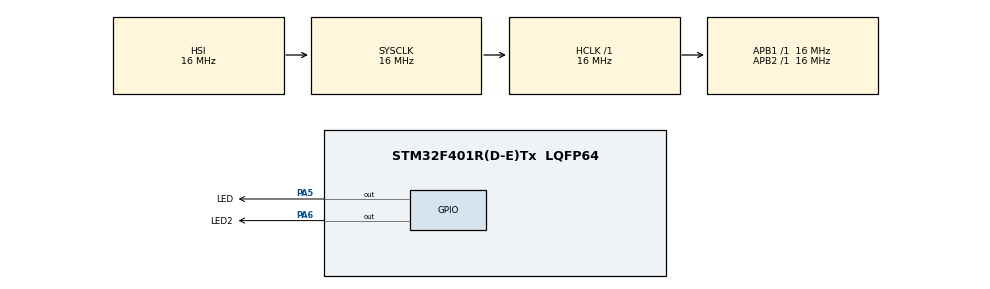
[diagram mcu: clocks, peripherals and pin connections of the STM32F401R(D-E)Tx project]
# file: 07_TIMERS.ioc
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Mcu.Family=STM32F4
Mcu.Name=STM32F401R(D-E)Tx
Mcu.Package=LQFP64
NVIC.PriorityGroup=NVIC_PRIORITYGROUP_4
NVIC.TIM1_TRG_COM_TIM11_IRQn=true\:0\:0\:false\:false\:true\:true\:true\:true
PA13.Mode=Serial_Wire
PA13.Signal=SYS_JTMS-SWDIO
PA14.Mode=Serial_Wire
PA14.Signal=SYS_JTCK-SWCLK
PA5.GPIO_Label=LED
PA5.Signal=GPIO_Output
PA6.GPIO_Label=LED2
PA6.Signal=GPIO_Output
ProjectManager.HeapSize=0x200
ProjectManager.StackSize=0x400
ProjectManager.TargetToolchain=STM32CubeIDE
RCC.AHBFreq_Value=16000000
RCC.APB1Freq_Value=16000000
RCC.APB2Freq_Value=16000000
RCC.CortexFreq_Value=16000000
RCC.HSE_VALUE=25000000
RCC.HSI_VALUE=16000000
RCC.LSE_VALUE=32768
RCC.SYSCLKFreq_VALUE=16000000
RCC.VCOOutputFreq_Value=192000000
TIM1.AutoReloadPreload=TIM_AUTORELOAD_PRELOAD_ENABLE
TIM1.Period=16000-1
TIM1.Prescaler=100-1
TIM11.AutoReloadPreload=TIM_AUTORELOAD_PRELOAD_ENABLE
TIM11.Period=16000-1
TIM11.Prescaler=100-1
VP_TIM11_VS_ClockSourceINT.Mode=Enable_Timer
VP_TIM1_VS_ClockSourceINT.Mode=Internal
board=custom

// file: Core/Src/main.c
/* USER CODE BEGIN Header */
/**
  ******************************************************************************
  * @file           : main.c
  * @brief          : Main program body
  ******************************************************************************
  * @attention
  *
  * Copyright (c) 2023 STMicroelectronics.
  * All rights reserved.
  *
  * This software is licensed under terms that can be found in the LICENSE file
  * in the root directory of this software component.
  * If no LICENSE file comes with this software, it is provided AS-IS.
  *
  ******************************************************************************
  */
/* USER CODE END Header */
#include "main.h"

TIM_HandleTypeDef htim1;
TIM_HandleTypeDef htim11;

void SystemClock_Config(void);
static void MX_GPIO_Init(void);
static void MX_TIM11_Init(void);
static void MX_TIM1_Init(void);

int main(void)
{

  /* MCU Configuration--------------------------------------------------------*/

  /* Reset of all peripherals, Initializes the Flash interface and the Systick. */
  HAL_Init();

  /* Configure the system clock */
  SystemClock_Config();

  /* USER CODE BEGIN SysInit */

  /*FORMULA DEL TIMER:
   *
   * ARR = ((TEMPORIZACION * FOSC)/(PREE + 1))-1
   *
   * EJM PARA 100 MS:
   *
   * ARR = ((100X10^-3 * 16X10^6) / ( 100 + 1 )) -1
   * ARR =  (1600000 / 101) -1
   * ARR =  15840.58 -> SI ENTRA EN EL REGISTRO DE 16B IT ARR
   *
   * ARR = 16000 -1
   * PREE = 100 - 1
   * */
  /* USER CODE END SysInit */

  /* Initialize all configured peripherals */
  MX_GPIO_Init();
  MX_TIM11_Init();
  MX_TIM1_Init();
  /* USER CODE BEGIN 2 */
  HAL_TIM_Base_Start_IT(&htim11);
  HAL_TIM_Base_Start_IT(&htim1);
  /* USER CODE END 2 */

  /* Infinite loop */
  while (1)
  {

  }
}

void SystemClock_Config(void)
{
  RCC_OscInitTypeDef RCC_OscInitStruct = {0};
  RCC_ClkInitTypeDef RCC_ClkInitStruct = {0};

  /** Configure the main internal regulator output voltage
  */
  __HAL_RCC_PWR_CLK_ENABLE();
  __HAL_PWR_VOLTAGESCALING_CONFIG(PWR_REGULATOR_VOLTAGE_SCALE2);

  /** Initializes the RCC Oscillators according to the specified parameters
  * in the RCC_OscInitTypeDef structure.
  */
  RCC_OscInitStruct.OscillatorType = RCC_OSCILLATORTYPE_HSI;
  RCC_OscInitStruct.HSIState = RCC_HSI_ON;
  RCC_OscInitStruct.HSICalibrationValue = RCC_HSICALIBRATION_DEFAULT;
  RCC_OscInitStruct.PLL.PLLState = RCC_PLL_NONE;
  if (HAL_RCC_OscConfig(&RCC_OscInitStruct) != HAL_OK)
  {
    Error_Handler();
  }

  /** Initializes the CPU, AHB and APB buses clocks
  */
  RCC_ClkInitStruct.ClockType = RCC_CLOCKTYPE_HCLK|RCC_CLOCKTYPE_SYSCLK
                              |RCC_CLOCKTYPE_PCLK1|RCC_CLOCKTYPE_PCLK2;
  RCC_ClkInitStruct.SYSCLKSource = RCC_SYSCLKSOURCE_HSI;
  RCC_ClkInitStruct.AHBCLKDivider = RCC_SYSCLK_DIV1;
  RCC_ClkInitStruct.APB1CLKDivider = RCC_HCLK_DIV1;
  RCC_ClkInitStruct.APB2CLKDivider = RCC_HCLK_DIV1;

  if (HAL_RCC_ClockConfig(&RCC_ClkInitStruct, FLASH_LATENCY_0) != HAL_OK)
  {
    Error_Handler();
  }
}

static void MX_TIM1_Init(void)
{

  TIM_ClockConfigTypeDef sClockSourceConfig = {0};
  TIM_MasterConfigTypeDef sMasterConfig = {0};

  htim1.Instance = TIM1;
  htim1.Init.Prescaler = 100-1;
  htim1.Init.CounterMode = TIM_COUNTERMODE_UP;
  htim1.Init.Period = 16000-1;
  htim1.Init.ClockDivision = TIM_CLOCKDIVISION_DIV1;
  htim1.Init.RepetitionCounter = 0;
  htim1.Init.AutoReloadPreload = TIM_AUTORELOAD_PRELOAD_ENABLE;
  if (HAL_TIM_Base_Init(&htim1) != HAL_OK)
  {
    Error_Handler();
  }
  sClockSourceConfig.ClockSource = TIM_CLOCKSOURCE_INTERNAL;
  if (HAL_TIM_ConfigClockSource(&htim1, &sClockSourceConfig) != HAL_OK)
  {
    Error_Handler();
  }
  sMasterConfig.MasterOutputTrigger = TIM_TRGO_RESET;
  sMasterConfig.MasterSlaveMode = TIM_MASTERSLAVEMODE_DISABLE;
  if (HAL_TIMEx_MasterConfigSynchronization(&htim1, &sMasterConfig) != HAL_OK)
  {
    Error_Handler();
  }

}

static void MX_TIM11_Init(void)
{

  htim11.Instance = TIM11;
  htim11.Init.Prescaler = 100-1;
  htim11.Init.CounterMode = TIM_COUNTERMODE_UP;
  htim11.Init.Period = 16000-1;
  htim11.Init.ClockDivision = TIM_CLOCKDIVISION_DIV1;
  htim11.Init.AutoReloadPreload = TIM_AUTORELOAD_PRELOAD_ENABLE;
  if (HAL_TIM_Base_Init(&htim11) != HAL_OK)
  {
    Error_Handler();
  }

}

static void MX_GPIO_Init(void)
{
  GPIO_InitTypeDef GPIO_InitStruct = {0};

  /* GPIO Ports Clock Enable */
  __HAL_RCC_GPIOA_CLK_ENABLE();

  /*Configure GPIO pin Output Level */
  HAL_GPIO_WritePin(GPIOA, LED_Pin|LED2_Pin, GPIO_PIN_RESET);

  /*Configure GPIO pins : LED_Pin LED2_Pin */
  GPIO_InitStruct.Pin = LED_Pin|LED2_Pin;
  GPIO_InitStruct.Mode = GPIO_MODE_OUTPUT_PP;
  GPIO_InitStruct.Pull = GPIO_NOPULL;
  GPIO_InitStruct.Speed = GPIO_SPEED_FREQ_LOW;
  HAL_GPIO_Init(GPIOA, &GPIO_InitStruct);

}

/* USER CODE BEGIN 4 */
void HAL_TIM_PeriodElapsedCallback(TIM_HandleTypeDef *htim){
	if(htim == &htim11){
		HAL_GPIO_TogglePin(GPIOA, GPIO_PIN_5);

	}
	if(htim == &htim1){
			HAL_GPIO_TogglePin(GPIOA, GPIO_PIN_6);

	}
}
/* USER CODE END 4 */

void Error_Handler(void)
{
  __disable_irq();
  while (1)
  {
  }
}
